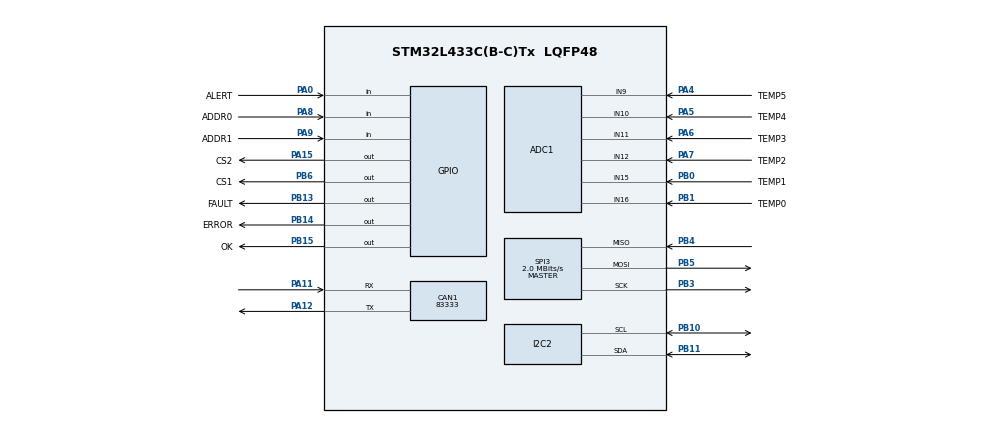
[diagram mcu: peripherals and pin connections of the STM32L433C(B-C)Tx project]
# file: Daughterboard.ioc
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ADC1.Channel-0\#ChannelRegularConversion=ADC_CHANNEL_9
ADC1.NbrOfConversionFlag=1
ADC1.OffsetNumber-0\#ChannelRegularConversion=ADC_OFFSET_NONE
ADC1.Rank-0\#ChannelRegularConversion=1
ADC1.SamplingTime-0\#ChannelRegularConversion=ADC_SAMPLETIME_2CYCLES_5
ADC1.master=1
CAN1.CalculateBaudRate=83333
CAN1.CalculateTimeBit=12000
CAN1.CalculateTimeQuantum=4000.0
FREERTOS.Tasks01=defaultTask,24,128,StartDefaultTask,Default,NULL,Dynamic,NULL,NULL;CheckVoltages,43,128,CheckVoltagesCheck,Default,NULL,Dynamic,NULL,NULL;CheckTemps,42,128,CheckTemp,Default,NULL,Dynamic,NULL,NULL;CANMessages,40,128,CANMessage,Default,NULL,Dynamic,NULL,NULL
I2C2.Timing=0x00100D14
Mcu.Family=STM32L4
Mcu.Name=STM32L433C(B-C)Tx
Mcu.Package=LQFP48
NVIC.PriorityGroup=NVIC_PRIORITYGROUP_4
PA0.GPIO_Label=ALERT
PA0.Signal=GPIO_Input
PA11.Mode=CAN_Activate
PA11.Signal=CAN1_RX
PA12.Mode=CAN_Activate
PA12.Signal=CAN1_TX
PA13\ (JTMS-SWDIO).Mode=Serial_Wire
PA13\ (JTMS-SWDIO).Signal=SYS_JTMS-SWDIO
PA14\ (JTCK-SWCLK).Mode=Serial_Wire
PA14\ (JTCK-SWCLK).Signal=SYS_JTCK-SWCLK
PA15\ (JTDI).GPIO_Label=CS2
PA15\ (JTDI).Signal=GPIO_Output
PA4.GPIO_Label=TEMP5
PA4.Signal=ADCx_IN9
PA5.GPIO_Label=TEMP4
PA5.Signal=ADCx_IN10
PA6.GPIO_Label=TEMP3
PA6.Signal=ADCx_IN11
PA7.GPIO_Label=TEMP2
PA7.Signal=ADCx_IN12
PA8.GPIO_Label=ADDR0
PA8.Signal=GPIO_Input
PA9.GPIO_Label=ADDR1
PA9.Signal=GPIO_Input
PB0.GPIO_Label=TEMP1
PB0.Signal=ADCx_IN15
PB1.GPIO_Label=TEMP0
PB1.Signal=ADCx_IN16
PB10.Mode=I2C
PB10.Signal=I2C2_SCL
PB11.Mode=I2C
PB11.Signal=I2C2_SDA
PB13.GPIO_Label=FAULT
PB13.Signal=GPIO_Output
PB14.GPIO_Label=ERROR
PB14.Signal=GPIO_Output
PB15.GPIO_Label=OK
PB15.Signal=GPIO_Output
PB3\ (JTDO-TRACESWO).Mode=Full_Duplex_Master
PB3\ (JTDO-TRACESWO).Signal=SPI3_SCK
PB4\ (NJTRST).Mode=Full_Duplex_Master
PB4\ (NJTRST).Signal=SPI3_MISO
PB5.Mode=Full_Duplex_Master
PB5.Signal=SPI3_MOSI
PB6.GPIO_Label=CS1
PB6.Signal=GPIO_Output
PC14-OSC32_IN\ (PC14).Mode=LSE-External-Oscillator
PC14-OSC32_IN\ (PC14).Signal=RCC_OSC32_IN
PC15-OSC32_OUT\ (PC15).Mode=LSE-External-Oscillator
PC15-OSC32_OUT\ (PC15).Signal=RCC_OSC32_OUT
ProjectManager.HeapSize=0x200
ProjectManager.StackSize=0x400
ProjectManager.TargetToolchain=Makefile
RCC.ADCFreq_Value=32000000
RCC.HSE_VALUE=8000000
RCC.HSI48_VALUE=48000000
RCC.HSI_VALUE=16000000
RCC.MSI_VALUE=4000000
RCC.PLLSAI1N=16
RCC.USBFreq_Value=32000000
RCC.VCOOutputFreq_Value=32000000
SH.ADCx_IN10.0=ADC1_IN10,IN10-Single-Ended
SH.ADCx_IN11.0=ADC1_IN11,IN11-Single-Ended
SH.ADCx_IN12.0=ADC1_IN12,IN12-Single-Ended
SH.ADCx_IN15.0=ADC1_IN15,IN15-Single-Ended
SH.ADCx_IN16.0=ADC1_IN16,IN16-Single-Ended
SH.ADCx_IN9.0=ADC1_IN9,IN9-Single-Ended
SPI3.CalculateBaudRate=2.0 MBits/s
SPI3.Direction=SPI_DIRECTION_2LINES
SPI3.Mode=SPI_MODE_MASTER
SPI3.VirtualType=VM_MASTER
VP_FREERTOS_VS_CMSIS_V2.Mode=CMSIS_V2
board=custom

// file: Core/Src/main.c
/* USER CODE BEGIN Header */
/**
  ******************************************************************************
  * @file           : main.c
  * @brief          : Main program body
  ******************************************************************************
  * @attention
  *
  * Copyright (c) 2026 STMicroelectronics.
  * All rights reserved.
  *
  * This software is licensed under terms that can be found in the LICENSE file
  * in the root directory of this software component.
  * If no LICENSE file comes with this software, it is provided AS-IS.
  *
  ******************************************************************************
  */
/* USER CODE END Header */
#include "main.h"
#include "cmsis_os.h"

/* USER CODE BEGIN Includes */
#include "user_threads.h"
/* USER CODE END Includes */

ADC_HandleTypeDef hadc1;

CAN_HandleTypeDef hcan1;

I2C_HandleTypeDef hi2c2;

SPI_HandleTypeDef hspi3;

/* Definitions for defaultTask */
osThreadId_t defaultTaskHandle;
const osThreadAttr_t defaultTask_attributes = {
  .name = "defaultTask",
  .stack_size = 128 * 4,
  .priority = (osPriority_t) osPriorityNormal,
};
/* Definitions for CheckVoltages */
osThreadId_t CheckVoltagesHandle;
const osThreadAttr_t CheckVoltages_attributes = {
  .name = "CheckVoltages",
  .stack_size = 128 * 4,
  .priority = (osPriority_t) osPriorityHigh3,
};
/* Definitions for CheckTemps */
osThreadId_t CheckTempsHandle;
const osThreadAttr_t CheckTemps_attributes = {
  .name = "CheckTemps",
  .stack_size = 128 * 4,
  .priority = (osPriority_t) osPriorityHigh2,
};
/* Definitions for CANMessages */
osThreadId_t CANMessagesHandle;
const osThreadAttr_t CANMessages_attributes = {
  .name = "CANMessages",
  .stack_size = 128 * 4,
  .priority = (osPriority_t) osPriorityHigh,
};

void SystemClock_Config(void);
static void MX_GPIO_Init(void);
static void MX_ADC1_Init(void);
static void MX_CAN1_Init(void);
static void MX_I2C2_Init(void);
static void MX_SPI3_Init(void);
void StartDefaultTask(void *argument);
void CheckVoltagesCheck(void *argument);
void CheckTemp(void *argument);
void CANMessage(void *argument);

int main(void)
{

  /* MCU Configuration--------------------------------------------------------*/

  /* Reset of all peripherals, Initializes the Flash interface and the Systick. */
  HAL_Init();

  /* Configure the system clock */
  SystemClock_Config();

  /* Initialize all configured peripherals */
  MX_GPIO_Init();
  MX_ADC1_Init();
  MX_CAN1_Init();
  MX_I2C2_Init();
  MX_SPI3_Init();

  /* Init scheduler */
  osKernelInitialize();

  /* Create the thread(s) */
  /* creation of defaultTask */
  defaultTaskHandle = osThreadNew(StartDefaultTask, NULL, &defaultTask_attributes);

  /* creation of CheckVoltages */
  CheckVoltagesHandle = osThreadNew(CheckVoltagesCheck, NULL, &CheckVoltages_attributes);

  /* creation of CheckTemps */
  CheckTempsHandle = osThreadNew(CheckTemp, NULL, &CheckTemps_attributes);

  /* creation of CANMessages */
  CANMessagesHandle = osThreadNew(CANMessage, NULL, &CANMessages_attributes);

  /* Start scheduler */
  osKernelStart();

  /* We should never get here as control is now taken by the scheduler */

  /* Infinite loop */
  while (1)
  {

  }
}

void SystemClock_Config(void)
{
  RCC_OscInitTypeDef RCC_OscInitStruct = {0};
  RCC_ClkInitTypeDef RCC_ClkInitStruct = {0};

  /** Configure the main internal regulator output voltage
  */
  if (HAL_PWREx_ControlVoltageScaling(PWR_REGULATOR_VOLTAGE_SCALE1) != HAL_OK)
  {
    Error_Handler();
  }

  /** Configure LSE Drive Capability
  */
  HAL_PWR_EnableBkUpAccess();
  __HAL_RCC_LSEDRIVE_CONFIG(RCC_LSEDRIVE_LOW);

  /** Initializes the RCC Oscillators according to the specified parameters
  * in the RCC_OscInitTypeDef structure.
  */
  RCC_OscInitStruct.OscillatorType = RCC_OSCILLATORTYPE_LSE|RCC_OSCILLATORTYPE_MSI;
  RCC_OscInitStruct.LSEState = RCC_LSE_ON;
  RCC_OscInitStruct.MSIState = RCC_MSI_ON;
  RCC_OscInitStruct.MSICalibrationValue = 0;
  RCC_OscInitStruct.MSIClockRange = RCC_MSIRANGE_6;
  RCC_OscInitStruct.PLL.PLLState = RCC_PLL_NONE;
  if (HAL_RCC_OscConfig(&RCC_OscInitStruct) != HAL_OK)
  {
    Error_Handler();
  }

  /** Initializes the CPU, AHB and APB buses clocks
  */
  RCC_ClkInitStruct.ClockType = RCC_CLOCKTYPE_HCLK|RCC_CLOCKTYPE_SYSCLK
                              |RCC_CLOCKTYPE_PCLK1|RCC_CLOCKTYPE_PCLK2;
  RCC_ClkInitStruct.SYSCLKSource = RCC_SYSCLKSOURCE_MSI;
  RCC_ClkInitStruct.AHBCLKDivider = RCC_SYSCLK_DIV1;
  RCC_ClkInitStruct.APB1CLKDivider = RCC_HCLK_DIV1;
  RCC_ClkInitStruct.APB2CLKDivider = RCC_HCLK_DIV1;

  if (HAL_RCC_ClockConfig(&RCC_ClkInitStruct, FLASH_LATENCY_0) != HAL_OK)
  {
    Error_Handler();
  }

  /** Enable MSI Auto calibration
  */
  HAL_RCCEx_EnableMSIPLLMode();
}

static void MX_ADC1_Init(void)
{

  ADC_ChannelConfTypeDef sConfig = {0};

  /** Common config
  */
  hadc1.Instance = ADC1;
  hadc1.Init.ClockPrescaler = ADC_CLOCK_ASYNC_DIV1;
  hadc1.Init.Resolution = ADC_RESOLUTION_12B;
  hadc1.Init.DataAlign = ADC_DATAALIGN_RIGHT;
  hadc1.Init.ScanConvMode = ADC_SCAN_DISABLE;
  hadc1.Init.EOCSelection = ADC_EOC_SINGLE_CONV;
  hadc1.Init.LowPowerAutoWait = DISABLE;
  hadc1.Init.ContinuousConvMode = DISABLE;
  hadc1.Init.NbrOfConversion = 1;
  hadc1.Init.DiscontinuousConvMode = DISABLE;
  hadc1.Init.ExternalTrigConv = ADC_SOFTWARE_START;
  hadc1.Init.ExternalTrigConvEdge = ADC_EXTERNALTRIGCONVEDGE_NONE;
  hadc1.Init.DMAContinuousRequests = DISABLE;
  hadc1.Init.Overrun = ADC_OVR_DATA_PRESERVED;
  hadc1.Init.OversamplingMode = DISABLE;
  if (HAL_ADC_Init(&hadc1) != HAL_OK)
  {
    Error_Handler();
  }

  /** Configure Regular Channel
  */
  sConfig.Channel = ADC_CHANNEL_9;
  sConfig.Rank = ADC_REGULAR_RANK_1;
  sConfig.SamplingTime = ADC_SAMPLETIME_2CYCLES_5;
  sConfig.SingleDiff = ADC_SINGLE_ENDED;
  sConfig.OffsetNumber = ADC_OFFSET_NONE;
  sConfig.Offset = 0;
  if (HAL_ADC_ConfigChannel(&hadc1, &sConfig) != HAL_OK)
  {
    Error_Handler();
  }

}

static void MX_CAN1_Init(void)
{

  hcan1.Instance = CAN1;
  hcan1.Init.Prescaler = 16;
  hcan1.Init.Mode = CAN_MODE_NORMAL;
  hcan1.Init.SyncJumpWidth = CAN_SJW_1TQ;
  hcan1.Init.TimeSeg1 = CAN_BS1_1TQ;
  hcan1.Init.TimeSeg2 = CAN_BS2_1TQ;
  hcan1.Init.TimeTriggeredMode = DISABLE;
  hcan1.Init.AutoBusOff = DISABLE;
  hcan1.Init.AutoWakeUp = DISABLE;
  hcan1.Init.AutoRetransmission = DISABLE;
  hcan1.Init.ReceiveFifoLocked = DISABLE;
  hcan1.Init.TransmitFifoPriority = DISABLE;
  if (HAL_CAN_Init(&hcan1) != HAL_OK)
  {
    Error_Handler();
  }

}

static void MX_I2C2_Init(void)
{

  hi2c2.Instance = I2C2;
  hi2c2.Init.Timing = 0x00100D14;
  hi2c2.Init.OwnAddress1 = 0;
  hi2c2.Init.AddressingMode = I2C_ADDRESSINGMODE_7BIT;
  hi2c2.Init.DualAddressMode = I2C_DUALADDRESS_DISABLE;
  hi2c2.Init.OwnAddress2 = 0;
  hi2c2.Init.OwnAddress2Masks = I2C_OA2_NOMASK;
  hi2c2.Init.GeneralCallMode = I2C_GENERALCALL_DISABLE;
  hi2c2.Init.NoStretchMode = I2C_NOSTRETCH_DISABLE;
  if (HAL_I2C_Init(&hi2c2) != HAL_OK)
  {
    Error_Handler();
  }

  /** Configure Analogue filter
  */
  if (HAL_I2CEx_ConfigAnalogFilter(&hi2c2, I2C_ANALOGFILTER_ENABLE) != HAL_OK)
  {
    Error_Handler();
  }

  /** Configure Digital filter
  */
  if (HAL_I2CEx_ConfigDigitalFilter(&hi2c2, 0) != HAL_OK)
  {
    Error_Handler();
  }

}

static void MX_SPI3_Init(void)
{

  /* SPI3 parameter configuration*/
  hspi3.Instance = SPI3;
  hspi3.Init.Mode = SPI_MODE_MASTER;
  hspi3.Init.Direction = SPI_DIRECTION_2LINES;
  hspi3.Init.DataSize = SPI_DATASIZE_4BIT;
  hspi3.Init.CLKPolarity = SPI_POLARITY_LOW;
  hspi3.Init.CLKPhase = SPI_PHASE_1EDGE;
  hspi3.Init.NSS = SPI_NSS_SOFT;
  hspi3.Init.BaudRatePrescaler = SPI_BAUDRATEPRESCALER_2;
  hspi3.Init.FirstBit = SPI_FIRSTBIT_MSB;
  hspi3.Init.TIMode = SPI_TIMODE_DISABLE;
  hspi3.Init.CRCCalculation = SPI_CRCCALCULATION_DISABLE;
  hspi3.Init.CRCPolynomial = 7;
  hspi3.Init.CRCLength = SPI_CRC_LENGTH_DATASIZE;
  hspi3.Init.NSSPMode = SPI_NSS_PULSE_ENABLE;
  if (HAL_SPI_Init(&hspi3) != HAL_OK)
  {
    Error_Handler();
  }

}

static void MX_GPIO_Init(void)
{
  GPIO_InitTypeDef GPIO_InitStruct = {0};

  /* GPIO Ports Clock Enable */
  __HAL_RCC_GPIOC_CLK_ENABLE();
  __HAL_RCC_GPIOA_CLK_ENABLE();
  __HAL_RCC_GPIOB_CLK_ENABLE();

  /*Configure GPIO pin Output Level */
  HAL_GPIO_WritePin(GPIOB, FAULT_Pin|ERROR_Pin|OK_Pin|CS1_Pin, GPIO_PIN_RESET);

  /*Configure GPIO pin Output Level */
  HAL_GPIO_WritePin(CS2_GPIO_Port, CS2_Pin, GPIO_PIN_RESET);

  /*Configure GPIO pins : ALERT_Pin ADDR0_Pin ADDR1_Pin */
  GPIO_InitStruct.Pin = ALERT_Pin|ADDR0_Pin|ADDR1_Pin;
  GPIO_InitStruct.Mode = GPIO_MODE_INPUT;
  GPIO_InitStruct.Pull = GPIO_NOPULL;
  HAL_GPIO_Init(GPIOA, &GPIO_InitStruct);

  /*Configure GPIO pins : FAULT_Pin ERROR_Pin OK_Pin CS1_Pin */
  GPIO_InitStruct.Pin = FAULT_Pin|ERROR_Pin|OK_Pin|CS1_Pin;
  GPIO_InitStruct.Mode = GPIO_MODE_OUTPUT_PP;
  GPIO_InitStruct.Pull = GPIO_NOPULL;
  GPIO_InitStruct.Speed = GPIO_SPEED_FREQ_LOW;
  HAL_GPIO_Init(GPIOB, &GPIO_InitStruct);

  /*Configure GPIO pin : CS2_Pin */
  GPIO_InitStruct.Pin = CS2_Pin;
  GPIO_InitStruct.Mode = GPIO_MODE_OUTPUT_PP;
  GPIO_InitStruct.Pull = GPIO_NOPULL;
  GPIO_InitStruct.Speed = GPIO_SPEED_FREQ_LOW;
  HAL_GPIO_Init(CS2_GPIO_Port, &GPIO_InitStruct);

}

void StartDefaultTask(void *argument)
{
  for(;;)
  {
    osDelay(1);
  }
}

void CheckVoltagesCheck(void *argument)
{
  for(;;)
  {
    osDelay(1);
  }
}

void CheckTemp(void *argument)
{
  for(;;)
  {
    osDelay(1);
  }
}

void CANMessage(void *argument)
{
  for(;;)
  {
    osDelay(1);
  }
}

void Error_Handler(void)
{
  __disable_irq();
  while (1)
  {
  }
}
